# PIC18F05Q20 register map
Vendor: Microchip
Registers are 8-bit, read-write, reset 0x0 unless marked. A register's access mark holds for its fields unless they carry their own. Addresses are absolute, and some are shared; only a register's first bit layout is shown; [hi:lo] are bit positions; {n}, {i} and the like mark numbered series; 'fields as' and 'values as' point back to an identical list.

## wg_ecwg
0x199 CWG1CLK
  [0] CS
0x19A CWG1ISM
  [4:0] ISM
0x19B CWG1DBR
  [5:0] DBR
0x19C CWG1DBF
  [5:0] DBF
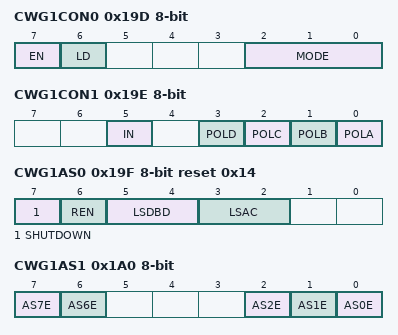
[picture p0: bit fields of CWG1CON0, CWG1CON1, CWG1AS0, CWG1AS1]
0x19D CWG1CON0
  [7] EN, [6] LD, [2:0] MODE
0x19E CWG1CON1 reset not defined — (power-on value --x-0000)
  [5] IN ro, [3] POLD, [2] POLC, [1] POLB, [0] POLA
0x19F CWG1AS0 reset 0x14
  [7] SHUTDOWN, [6] REN, [5:4] LSDBD, [3:2] LSAC
0x1A0 CWG1AS1
  [7] AS7E, [6] AS6E, [2] AS2E, [1] AS1E, [0] AS0E
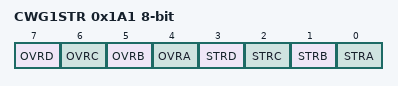
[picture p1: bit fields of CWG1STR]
0x1A1 CWG1STR
  [7] OVRD, [6] OVRC, [5] OVRB, [4] OVRA, [3] STRD, [2] STRC, [1] STRB, [0] STRA

## cla_clc
0x1A4 CLCSELECT
  [1:0] SLCT
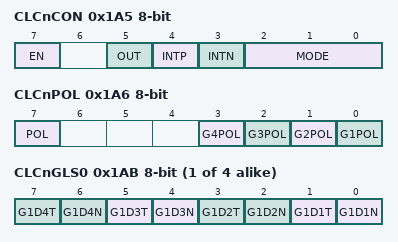
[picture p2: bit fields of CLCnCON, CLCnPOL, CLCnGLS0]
0x1A5 CLCnCON — Configurable logic cell control
  [7] EN, [5] OUT ro, [4] INTP, [3] INTN, [2:0] MODE
0x1A6 CLCnPOL reset not defined — Polarity control (power-on value 0---xxxx)
  [7] POL, [n-1] G{n}POL (n=1..4)
{0x1A7+i} CLCnSEL{i} reset not defined (i=0..3) — Input select register 1 (power-on value --xxxxxx)
  [5:0] D{i+1}S
{0x1AB+i} CLCnGLS{i} reset not defined (i=0..3) — Gate logic select register {i} (power-on value xxxxxxxx)
  [2n-1] G{i+1}D{n}T (n=1..4), [2n-2] G{i+1}D{n}N (n=1..4)

## uart_protocol
0x1AF U1RXB ro
  [7:0] RXB
0x1B0 U1RXCHK
  [7:0] RXCHK
0x1B1 U1TXB
  [7:0] TXB
0x1B2 U1TXCHK
  [7:0] TXCHK
0x1B3 U1P1L
  [7:0] P1L
{0x1B2+2i} U1P{i}H (i=1..3)
  [0] P{i}H
0x1B5 U1P2L
  [7:0] P2L
0x1B7 U1P3L reset not defined — (power-on value xxxxxxxx)
  [7:0] P3L
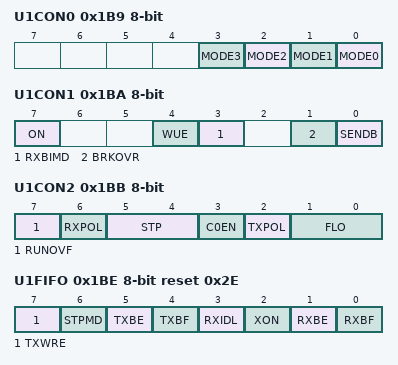
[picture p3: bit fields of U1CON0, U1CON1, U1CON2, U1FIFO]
0x1B9 U1CON0
  [n] MODE{n} (n=0..3)
0x1BA U1CON1
  [7] ON, [4] WUE, [3] RXBIMD, [1] BRKOVR, [0] SENDB
0x1BB U1CON2
  [7] RUNOVF, [6] RXPOL, [5:4] STP, [3] C0EN, [2] TXPOL, [1:0] FLO
0x1BC U1BRGL
  [7:0] BRGL
0x1BD U1BRGH
  [7:0] BRGH
0x1BE U1FIFO reset 0x2E
  [7] TXWRE, [6] STPMD, [5] TXBE, [4] TXBF ro, [3] RXIDL ro, [2] XON ro, [1] RXBE ro, [0] RXBF ro
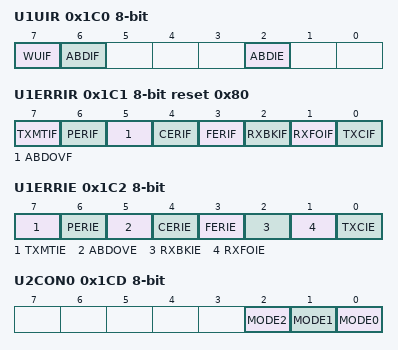
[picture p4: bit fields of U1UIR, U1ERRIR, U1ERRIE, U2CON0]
0x1C0 U1UIR
  [7] WUIF, [6] ABDIF, [2] ABDIE
0x1C1 U1ERRIR reset 0x80
  [7] TXMTIF, [6] PERIF, [5] ABDOVF, [4] CERIF, [3] FERIF, [2] RXBKIF, [1] RXFOIF, [0] TXCIF
0x1C2 U1ERRIE
  [7] TXMTIE, [6] PERIE, [5] ABDOVE, [4] CERIE, [3] FERIE, [2] RXBKIE, [1] RXFOIE, [0] TXCIE
0x1C3 U2RXB ro
  [7:0] RXB
0x1C5 U2TXB
  [7:0] TXB
0x1C7 U2P1L
  [7:0] P1L
0x1C9 U2P2L
  [7:0] P2L
0x1CB U2P3L reset not defined — (power-on value xxxxxxxx)
  [7:0] P3L
0x1CD U2CON0
  [2] MODE2, [1] MODE1, [0] MODE0
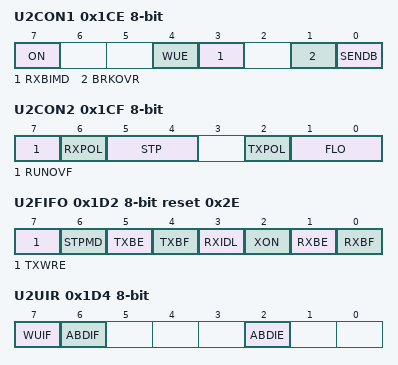
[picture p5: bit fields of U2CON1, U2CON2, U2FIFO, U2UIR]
0x1CE U2CON1
  [7] ON, [4] WUE, [3] RXBIMD, [1] BRKOVR, [0] SENDB
0x1CF U2CON2
  [7] RUNOVF, [6] RXPOL, [5:4] STP, [2] TXPOL, [1:0] FLO
0x1D0 U2BRGL
  [7:0] BRGL
0x1D1 U2BRGH
  [7:0] BRGH
0x1D2 U2FIFO reset 0x2E
  fields as U1FIFO
0x1D4 U2UIR
  [7] WUIF, [6] ABDIF, [2] ABDIE
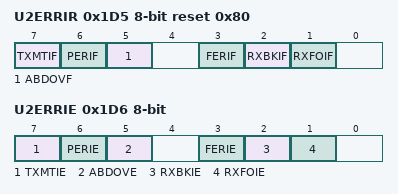
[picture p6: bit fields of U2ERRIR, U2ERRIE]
0x1D5 U2ERRIR reset 0x80
  [7] TXMTIF, [6] PERIF, [5] ABDOVF, [3] FERIF, [2] RXBKIF, [1] RXFOIF
0x1D6 U2ERRIE
  [7] TXMTIE, [6] PERIE, [5] ABDOVE, [3] FERIE, [2] RXBKIE, [1] RXFOIE

## spi
0x1D7 SPI1RXB ro reset not defined — (power-on value xxxxxxxx)
  [7:0] RXB
0x1D8 SPI1TXB wo reset not defined — (power-on value xxxxxxxx)
  [7:0] TXB
0x1D9 SPI1TCNTL
  [7:0] TCNTL
0x1DA SPI1TCNTH
  [2:0] TCNTH
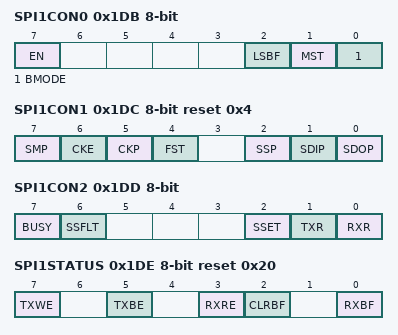
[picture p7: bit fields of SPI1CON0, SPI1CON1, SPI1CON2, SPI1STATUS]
0x1DB SPI1CON0
  [7] EN, [2] LSBF, [1] MST, [0] BMODE
0x1DC SPI1CON1 reset 0x4
  [7] SMP, [6] CKE, [5] CKP, [4] FST, [2] SSP, [1] SDIP, [0] SDOP
0x1DD SPI1CON2
  [7] BUSY ro, [6] SSFLT ro, [2] SSET, [1] TXR, [0] RXR
0x1DE SPI1STATUS reset 0x20
  [7] TXWE — (can only be cleared)
  [5] TXBE ro
  [3] RXRE — (can only be cleared)
  [2] CLRBF — (can only be set)
  [0] RXBF ro
0x1DF SPI1TWIDTH
  [2:0] TWIDTH
0x1E0 SPI1BAUD
  [7:0] BAUD
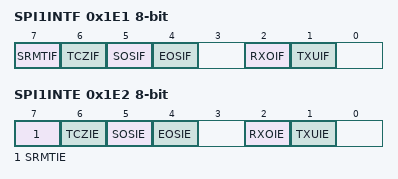
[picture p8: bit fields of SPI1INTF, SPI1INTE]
0x1E1 SPI1INTF
  [7] SRMTIF, [6] TCZIF, [5] SOSIF, [4] EOSIF, [2] RXOIF, [1] TXUIF
0x1E2 SPI1INTE
  [7] SRMTIE, [6] TCZIE, [5] SOSIE, [4] EOSIE, [2] RXOIE, [1] TXUIE
0x1E3 SPI1CLK
  [3:0] CLKSEL

## i2c
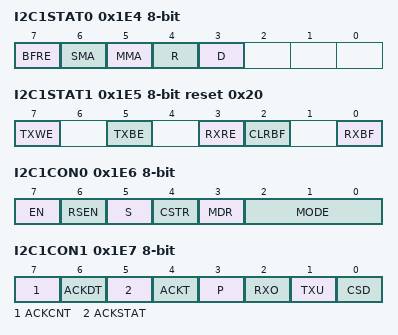
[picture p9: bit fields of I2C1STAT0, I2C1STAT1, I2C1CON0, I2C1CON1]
0x1E4 I2C1STAT0 ro — I2C STATUS REGISTER 0
  [7] BFRE
  [6] SMA
  [5] MMA
  [4] R — Read/Write Information bit
  [3] D — Data/Address bit
0x1E5 I2C1STAT1 reset 0x20 — I2C STATUS REGISTER 1
  [7] TXWE
  [5] TXBE ro
  [3] RXRE
  [2] CLRBF — (can only be set)
  [0] RXBF ro
0x1E6 I2C1CON0 — I2C CONTROL REGISTER 0
  [7] EN
  [6] RSEN
  [5] S — (can only be set)
  [4] CSTR — (can only be cleared)
  [3] MDR ro
  [2:0] MODE
0x1E7 I2C1CON1 — I2C CONTROL REGISTER 1
  [7] ACKCNT
  [6] ACKDT
  [5] ACKSTAT ro
  [4] ACKT ro
  [3] P — (can only be set)
  [2] RXO
  [1] TXU
  [0] CSD
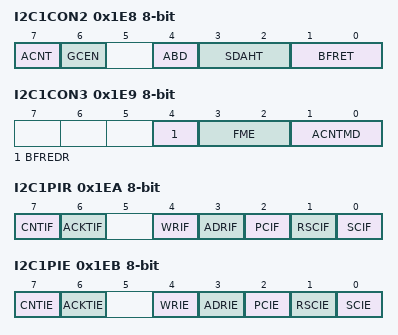
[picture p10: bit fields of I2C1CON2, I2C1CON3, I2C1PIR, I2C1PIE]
0x1E8 I2C1CON2 — I2C CONTROL REGISTER 2
  [7] ACNT, [6] GCEN, [4] ABD, [3:2] SDAHT, [1:0] BFRET
0x1E9 I2C1CON3 — I2C CONTROL REGISTER 3
  [4] BFREDR, [3:2] FME, [1:0] ACNTMD
0x1EA I2C1PIR — I2C PERIPHERAL INTERRUPT FLAG REGISTER
  [7] CNTIF, [6] ACKTIF, [4] WRIF, [3] ADRIF, [2] PCIF, [1] RSCIF, [0] SCIF
0x1EB I2C1PIE — I2C PERIPHERAL INTERRUPT ENABLE REGISTER
  [7] CNTIE, [6] ACKTIE, [4] WRIE, [3] ADRIE, [2] PCIE, [1] RSCIE, [0] SCIE
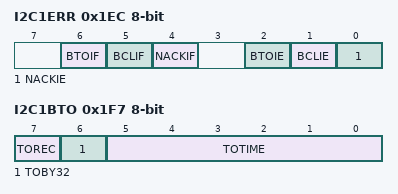
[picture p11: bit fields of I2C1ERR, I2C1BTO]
0x1EC I2C1ERR — I2C ERROR REGISTER
  [6] BTOIF, [5] BCLIF, [4] NACKIF, [2] BTOIE, [1] BCLIE, [0] NACKIE
0x1ED I2C1CNTL reset not defined — I2C BYTE COUNT REGISTER LOW BYTE (power-on value xxxxxxxx)
  [7:0] CNT
0x1EE I2C1CNTH reset not defined — I2C BYTE COUNT REGISTER HIGH BYTE (power-on value xxxxxxxx)
  [7:0] CNT
0x1EF I2C1RXB ro reset not defined — I2C RECEIVE BUFFER REGISTER (power-on value xxxxxxxx)
  [7:0] RXB
0x1F0 I2C1TXB wo reset not defined — I2C TRANSMIT BUFFER REGISTER (power-on value xxxxxxxx)
  [7:0] TXB
0x1F1 I2C1ADB0 reset not defined — I2C ADDRESS BUFFER REGISTER 0 (power-on value xxxxxxxx)
  [7:0] ADB
0x1F2 I2C1ADB1 reset not defined — I2C ADDRESS BUFFER REGISTER 1 (power-on value xxxxxxxx)
  [7:0] ADB
0x1F3 I2C1ADR0 reset 0xFF — I2C ADDRESS REGISTER 0
  [7:0] ADR
0x1F4 I2C1ADR1 reset 0xFE — I2C ADDRESS REGISTER 1
  [7:1] ADR
0x1F5 I2C1ADR2 reset 0xFF — I2C ADDRESS REGISTER 2
  [7:0] ADR
0x1F6 I2C1ADR3 reset 0xFE — I2C ADDRESS REGISTER 3
  [7:1] ADR
0x1F7 I2C1BTO — I2C BUS TIME OUT SELECTION REGISTER
  [7] TOREC, [6] TOBY32, [5:0] TOTIME
0x1F8 I2C1BAUD — I2C BAUD RATE PRESCALER REGISTER
  [7:0] BAUD
0x1F9 I2C1CLK — I2C CLOCK SELECTION REGISTER
  [3:0] CLK
0x1FA I2C1BTOC — I2C BUS TIMEOUT ISM REGISTER
  [2:0] BTOC
